# STM32H7B0xx register map
File version: 1.0
Registers are 32-bit, access not given, reset 0x0 unless marked. A register's access mark holds for its fields unless they carry their own. Offsets are from the block's base; [hi:lo] are bit positions; 'fields as' and 'values as' point back to an identical list.

## DFSDM1
Base 0x40017800
Same registers: DFSDM2 0x58006C00
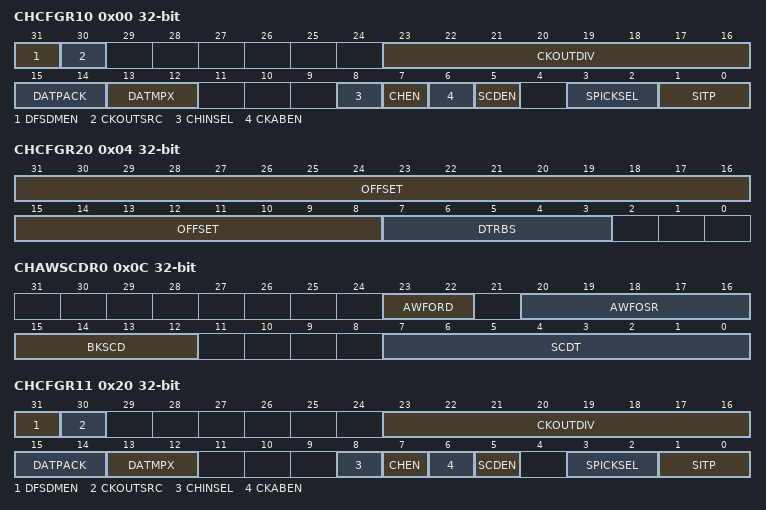
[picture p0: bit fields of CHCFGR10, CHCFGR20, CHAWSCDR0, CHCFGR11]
0x00 CHCFGR10
  [31] DFSDMEN, [30] CKOUTSRC, [23:16] CKOUTDIV, [15:14] DATPACK, [13:12] DATMPX, [8] CHINSEL, [7] CHEN, [6] CKABEN, [5] SCDEN, [3:2] SPICKSEL, [1:0] SITP
0x04 CHCFGR20
  [31:8] OFFSET, [7:3] DTRBS
0x0C CHAWSCDR0
  [23:22] AWFORD, [20:16] AWFOSR, [15:12] BKSCD, [7:0] SCDT
0x18 CHWDATAR0
0x20 CHCFGR11
  fields as CHCFGR10
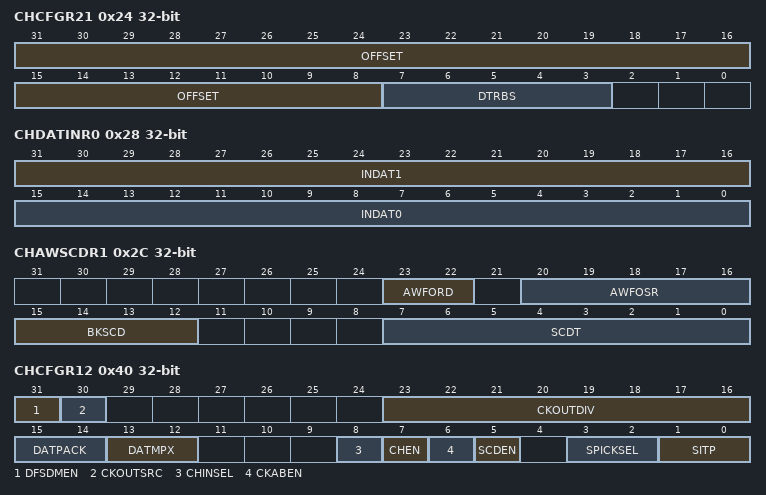
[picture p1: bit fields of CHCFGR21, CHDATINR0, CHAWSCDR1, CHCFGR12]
0x24 CHCFGR21
  [31:8] OFFSET, [7:3] DTRBS
0x28 CHDATINR0
  [31:16] INDAT1, [15:0] INDAT0
0x2C CHAWSCDR1
  [23:22] AWFORD, [20:16] AWFOSR, [15:12] BKSCD, [7:0] SCDT
0x38 CHWDATAR1
0x3C CHDLYR0
  [5:0] PLSSKP
0x40 CHCFGR12
  fields as CHCFGR10
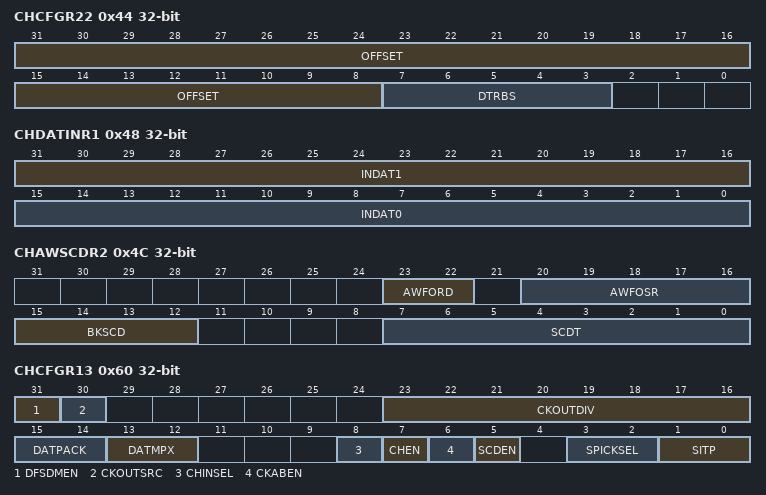
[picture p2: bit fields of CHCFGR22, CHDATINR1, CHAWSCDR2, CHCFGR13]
0x44 CHCFGR22
  [31:8] OFFSET, [7:3] DTRBS
0x48 CHDATINR1
  [31:16] INDAT1, [15:0] INDAT0
0x4C CHAWSCDR2
  [23:22] AWFORD, [20:16] AWFOSR, [15:12] BKSCD, [7:0] SCDT
0x58 CHWDATAR2
0x5C CHDLYR1
  [5:0] PLSSKP
0x60 CHCFGR13
  fields as CHCFGR10
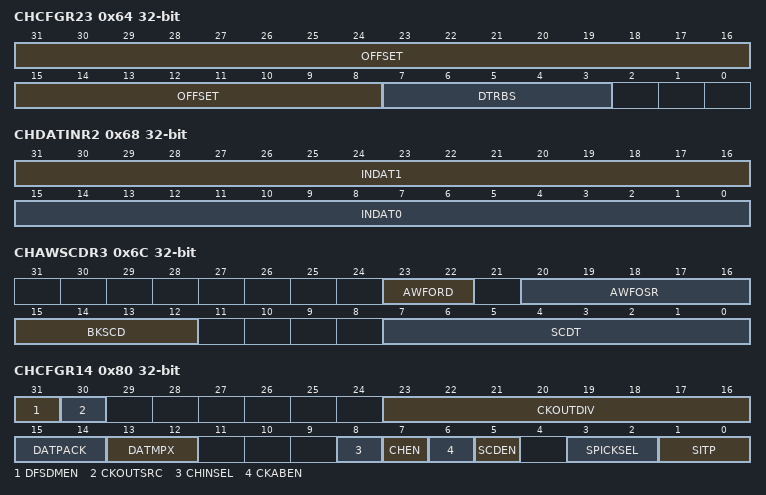
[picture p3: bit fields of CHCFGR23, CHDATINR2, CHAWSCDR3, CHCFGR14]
0x64 CHCFGR23
  [31:8] OFFSET, [7:3] DTRBS
0x68 CHDATINR2
  [31:16] INDAT1, [15:0] INDAT0
0x6C CHAWSCDR3
  [23:22] AWFORD, [20:16] AWFOSR, [15:12] BKSCD, [7:0] SCDT
0x78 CHWDATAR3
0x7C CHDLYR2
  [5:0] PLSSKP
0x80 CHCFGR14
  fields as CHCFGR10
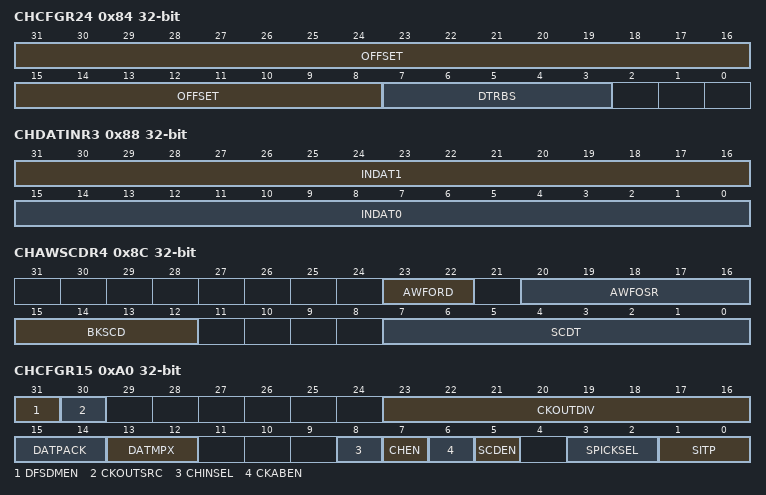
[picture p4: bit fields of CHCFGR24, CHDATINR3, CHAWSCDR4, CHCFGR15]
0x84 CHCFGR24
  [31:8] OFFSET, [7:3] DTRBS
0x88 CHDATINR3
  [31:16] INDAT1, [15:0] INDAT0
0x8C CHAWSCDR4
  [23:22] AWFORD, [20:16] AWFOSR, [15:12] BKSCD, [7:0] SCDT
0x98 CHWDATAR4
0x9C CHDLYR3
  [5:0] PLSSKP
0xA0 CHCFGR15
  fields as CHCFGR10
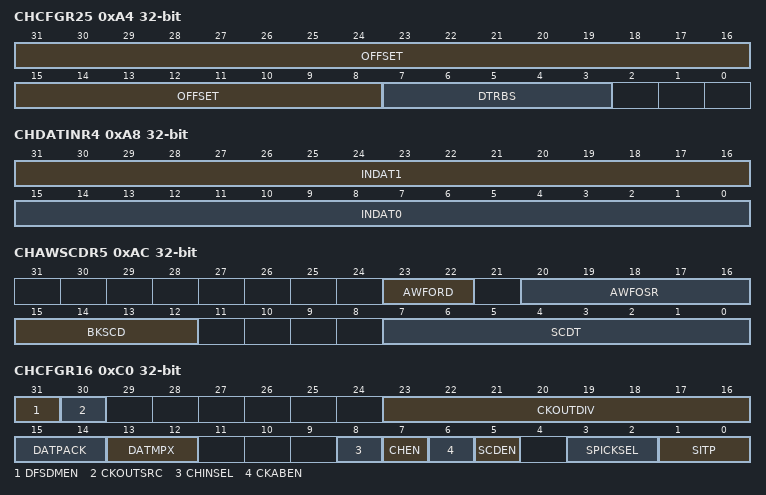
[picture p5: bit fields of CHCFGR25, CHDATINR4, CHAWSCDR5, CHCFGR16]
0xA4 CHCFGR25
  [31:8] OFFSET, [7:3] DTRBS
0xA8 CHDATINR4
  [31:16] INDAT1, [15:0] INDAT0
0xAC CHAWSCDR5
  [23:22] AWFORD, [20:16] AWFOSR, [15:12] BKSCD, [7:0] SCDT
0xB8 CHWDATAR5
0xBC CHDLYR4
  [5:0] PLSSKP
0xC0 CHCFGR16
  fields as CHCFGR10
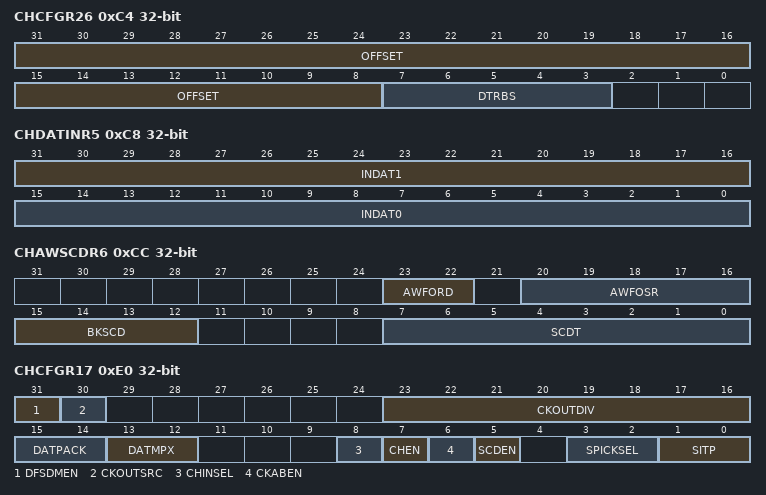
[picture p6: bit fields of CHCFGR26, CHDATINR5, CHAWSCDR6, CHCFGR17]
0xC4 CHCFGR26
  [31:8] OFFSET, [7:3] DTRBS
0xC8 CHDATINR5
  [31:16] INDAT1, [15:0] INDAT0
0xCC CHAWSCDR6
  [23:22] AWFORD, [20:16] AWFOSR, [15:12] BKSCD, [7:0] SCDT
0xD8 CHWDATAR6
0xDC CHDLYR5
  [5:0] PLSSKP
0xE0 CHCFGR17
  fields as CHCFGR10
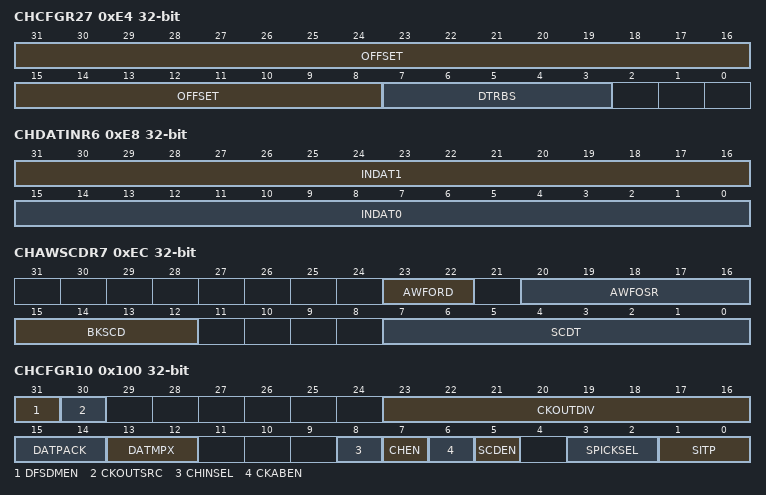
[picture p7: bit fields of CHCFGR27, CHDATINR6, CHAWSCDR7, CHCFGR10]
0xE4 CHCFGR27
  [31:8] OFFSET, [7:3] DTRBS
0xE8 CHDATINR6
  [31:16] INDAT1, [15:0] INDAT0
0xEC CHAWSCDR7
  [23:22] AWFORD, [20:16] AWFOSR, [15:12] BKSCD, [7:0] SCDT
0xF8 CHWDATAR7
0xFC CHDLYR6
  [5:0] PLSSKP
0x100 CHCFGR10
  fields as CHCFGR10
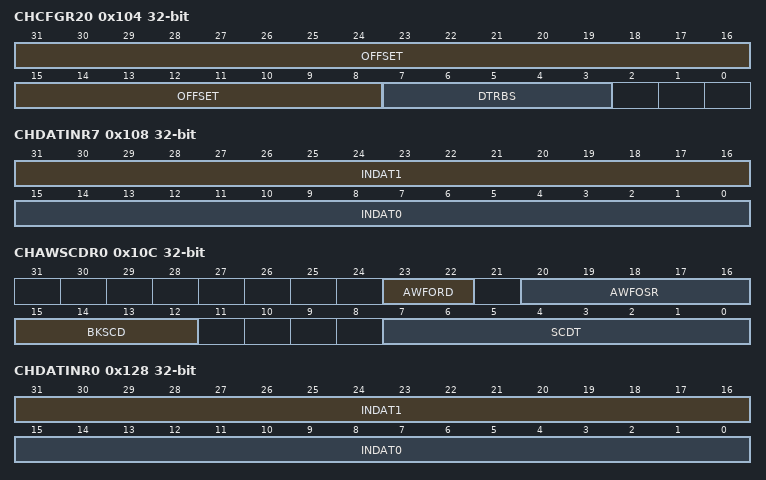
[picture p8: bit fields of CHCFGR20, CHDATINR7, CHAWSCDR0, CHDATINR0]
0x104 CHCFGR20
  [31:8] OFFSET, [7:3] DTRBS
0x108 CHDATINR7
  [31:16] INDAT1, [15:0] INDAT0
0x10C CHAWSCDR0
  [23:22] AWFORD, [20:16] AWFOSR, [15:12] BKSCD, [7:0] SCDT
0x118 CHWDATAR0
0x11C CHDLYR7
  [5:0] PLSSKP
0x128 CHDATINR0
  [31:16] INDAT1, [15:0] INDAT0
0x13C CHDLYR0
  [5:0] PLSSKP
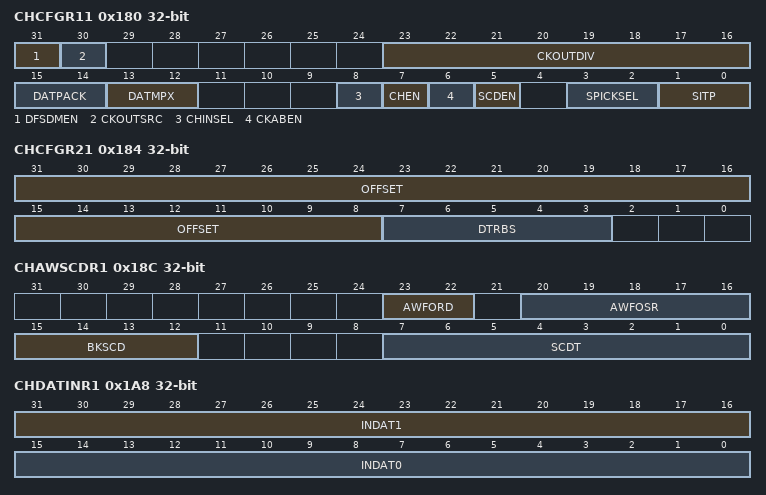
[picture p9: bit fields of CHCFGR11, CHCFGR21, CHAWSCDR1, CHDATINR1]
0x180 CHCFGR11
  fields as CHCFGR10
0x184 CHCFGR21
  [31:8] OFFSET, [7:3] DTRBS
0x18C CHAWSCDR1
  [23:22] AWFORD, [20:16] AWFOSR, [15:12] BKSCD, [7:0] SCDT
0x198 CHWDATAR1
0x1A8 CHDATINR1
  [31:16] INDAT1, [15:0] INDAT0
0x1BC CHDLYR1
  [5:0] PLSSKP
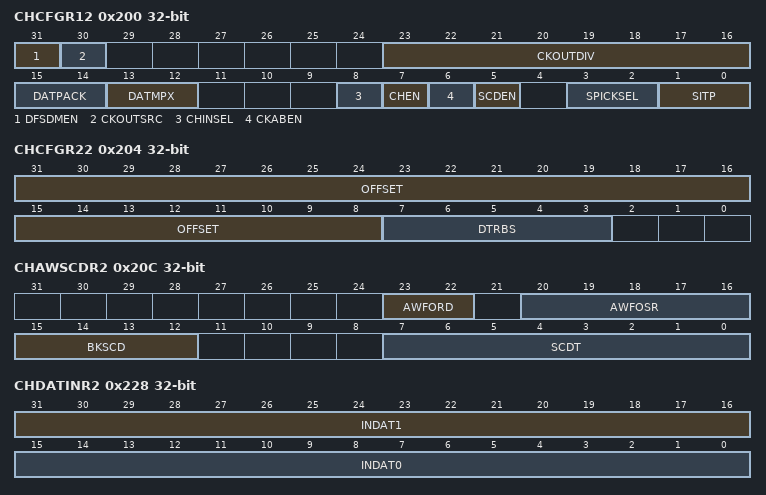
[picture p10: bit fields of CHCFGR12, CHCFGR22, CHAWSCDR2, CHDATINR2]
0x200 CHCFGR12
  fields as CHCFGR10
0x204 CHCFGR22
  [31:8] OFFSET, [7:3] DTRBS
0x20C CHAWSCDR2
  [23:22] AWFORD, [20:16] AWFOSR, [15:12] BKSCD, [7:0] SCDT
0x218 CHWDATAR2
0x228 CHDATINR2
  [31:16] INDAT1, [15:0] INDAT0
0x23C CHDLYR2
  [5:0] PLSSKP
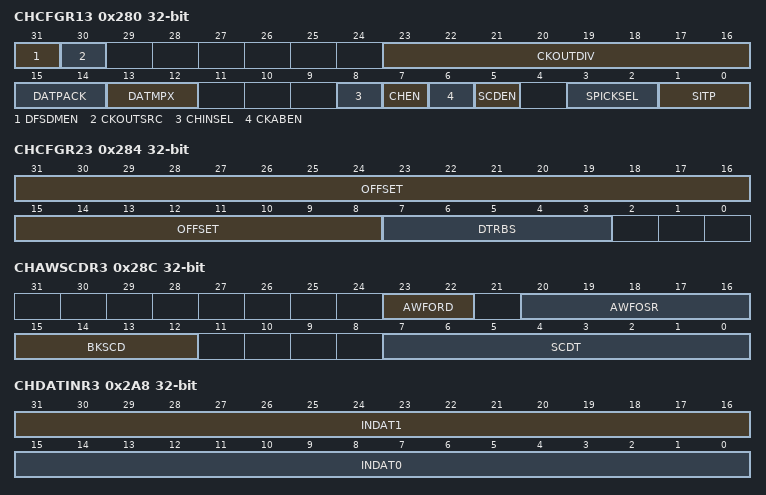
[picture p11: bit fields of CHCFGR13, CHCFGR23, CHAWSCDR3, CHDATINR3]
0x280 CHCFGR13
  fields as CHCFGR10
0x284 CHCFGR23
  [31:8] OFFSET, [7:3] DTRBS
0x28C CHAWSCDR3
  [23:22] AWFORD, [20:16] AWFOSR, [15:12] BKSCD, [7:0] SCDT
0x298 CHWDATAR3
0x2A8 CHDATINR3
  [31:16] INDAT1, [15:0] INDAT0
0x2BC CHDLYR3
  [5:0] PLSSKP
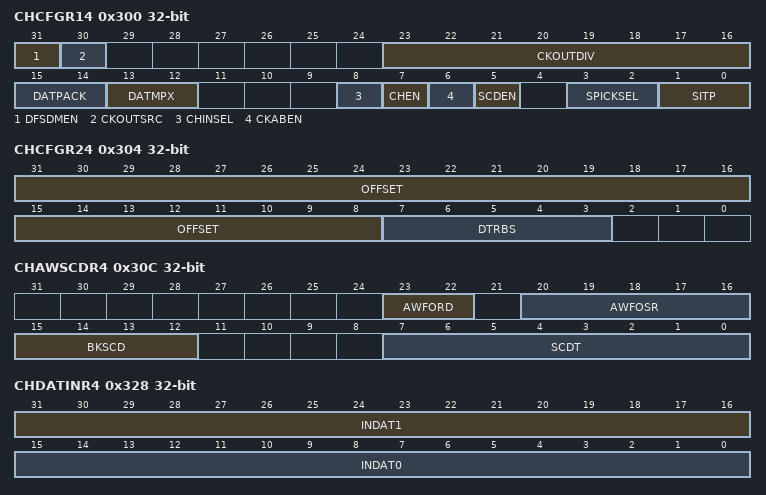
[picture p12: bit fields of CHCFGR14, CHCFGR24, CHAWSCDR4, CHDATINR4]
0x300 CHCFGR14
  fields as CHCFGR10
0x304 CHCFGR24
  [31:8] OFFSET, [7:3] DTRBS
0x30C CHAWSCDR4
  [23:22] AWFORD, [20:16] AWFOSR, [15:12] BKSCD, [7:0] SCDT
0x318 CHWDATAR4
0x328 CHDATINR4
  [31:16] INDAT1, [15:0] INDAT0
0x33C CHDLYR4
  [5:0] PLSSKP
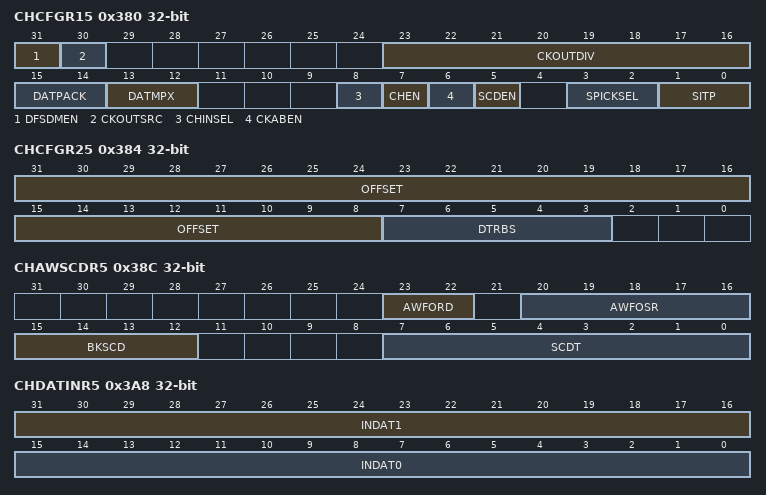
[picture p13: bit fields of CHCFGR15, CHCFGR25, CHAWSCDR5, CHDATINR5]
0x380 CHCFGR15
  fields as CHCFGR10
0x384 CHCFGR25
  [31:8] OFFSET, [7:3] DTRBS
0x38C CHAWSCDR5
  [23:22] AWFORD, [20:16] AWFOSR, [15:12] BKSCD, [7:0] SCDT
0x398 CHWDATAR5
0x3A8 CHDATINR5
  [31:16] INDAT1, [15:0] INDAT0
0x3BC CHDLYR5
  [5:0] PLSSKP
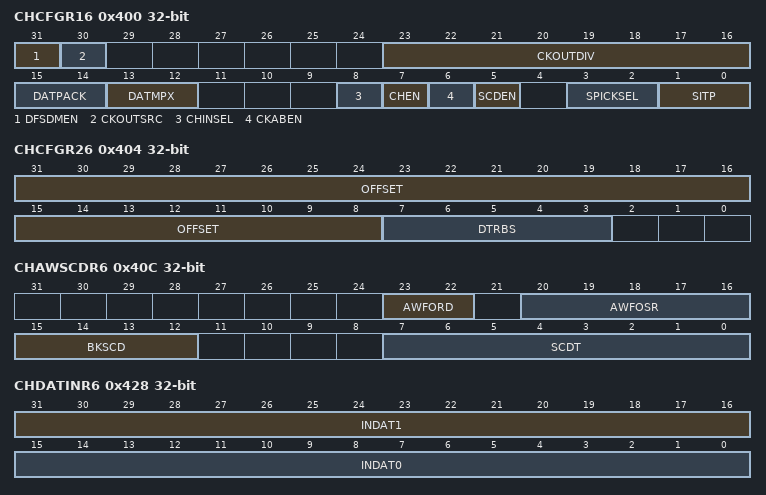
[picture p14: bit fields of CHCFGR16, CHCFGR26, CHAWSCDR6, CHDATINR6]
0x400 CHCFGR16
  fields as CHCFGR10
0x404 CHCFGR26
  [31:8] OFFSET, [7:3] DTRBS
0x40C CHAWSCDR6
  [23:22] AWFORD, [20:16] AWFOSR, [15:12] BKSCD, [7:0] SCDT
0x418 CHWDATAR6
0x428 CHDATINR6
  [31:16] INDAT1, [15:0] INDAT0
0x43C CHDLYR6
  [5:0] PLSSKP
0x480 CHCFGR17
  fields as CHCFGR10
0x484 CHCFGR27
  [31:8] OFFSET, [7:3] DTRBS
0x48C CHAWSCDR7
  [23:22] AWFORD, [20:16] AWFOSR, [15:12] BKSCD, [7:0] SCDT
0x498 CHWDATAR7
0x4A8 CHDATINR7
  [31:16] INDAT1, [15:0] INDAT0
0x4BC CHDLYR7
  [5:0] PLSSKP
0x17FEF400 CHCFGR10
  fields as CHCFGR10
0x17FEF404 CHCFGR20
  [31:8] OFFSET, [7:3] DTRBS
0x17FEF40C CHAWSCDR0
  [23:22] AWFORD, [20:16] AWFOSR, [15:12] BKSCD, [7:0] SCDT
0x17FEF418 CHWDATAR0
0x17FEF428 CHDATINR0
  [31:16] INDAT1, [15:0] INDAT0
0x17FEF43C CHDLYR0
  [5:0] PLSSKP
